# LPC43xx register map
File version: 5
Registers are 32-bit, read-write, reset 0x0 unless marked. A register's access mark holds for its fields unless they carry their own. Offsets are from the block's base; [hi:lo] are bit positions; {n}, {i} and the like mark numbered series.

## SPI — Product name title=UM10503 Chapter title=LPC43xx SPI Modification date=10/7/2011 Major revision=0 Minor revision=3
Base 0x40100000
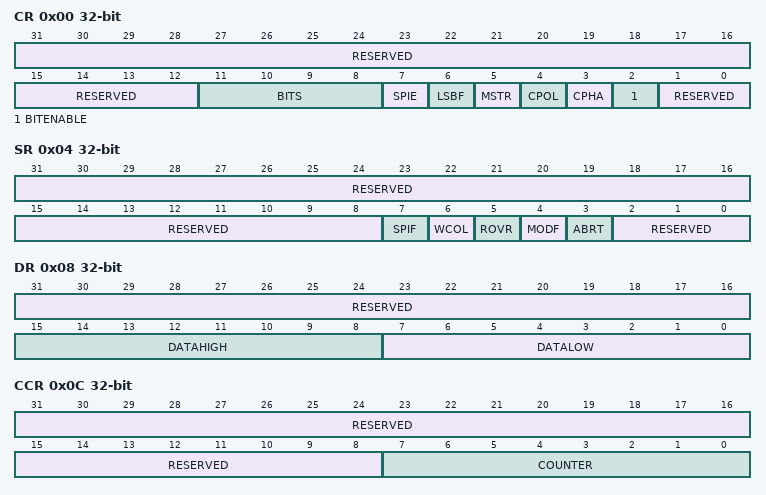
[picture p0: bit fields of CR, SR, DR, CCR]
0x00 CR — SPI Control Register. This register controls the operation of the SPI.
  [31:12] RESERVED — Reserved, user software should not write ones to reserved bits. The value read from a reserved bit is not defined.
  [11:8] BITS — When bit 2 of this register is 1, this field controls the number of bits per transfer:
    {v}={v}_BITS_PER_TRANSFER (v=8..15); 0=16_BITS_PER_TRANSFER
  [7] SPIE — Serial peripheral interrupt enable.
    0=INTBLOCK (SPI interrupts are inhibited.); 1=HWINT (A hardware interrupt is generated each time the SPIF or MODF bits are activated.)
  [6] LSBF — LSB First controls which direction each byte is shifted when transferred.
    0=MSB (SPI data is transferred MSB (bit 7) first.); 1=LSB (SPI data is transferred LSB (bit 0) first.)
  [5] MSTR — Master mode select.
    0=SLAVE (The SPI operates in Slave mode.); 1=MASTER (The SPI operates in Master mode.)
  [4] CPOL — Clock polarity control.
    0=SCK_IS_ACTIVE_HIGH_; 1=SCK_IS_ACTIVE_LOW_
  [3] CPHA — Clock phase control determines the relationship between the data and the clock on SPI transfers, and controls when a slave transfer is defined as starting and ending.
    0=FIRST_EDGE (Data is sampled on the first clock edge of SCK. A transfer starts and ends with activation and deactivation of the SSEL signal.); 1=SECOND_EDGE (Data is sampled on the second clock edge of the SCK. A transfer starts with the first clock edge, and ends with the last sampling edge when the SSEL signal is active.)
  [2] BITENABLE — The SPI controller sends and receives 8 bits of data per transfer.
    1=THE_SPI_CONTROLLER_S (The SPI controller sends and receives the number of bits selected by bits 11:8.)
  [1:0] RESERVED — Reserved, user software should not write ones to reserved bits. The value read from a reserved bit is not defined.
0x04 SR ro — SPI Status Register. This register shows the status of the SPI.
  [31:8] RESERVED — Reserved, user software should not write ones to reserved bits. The value read from a reserved bit is not defined.
  [7] SPIF — SPI transfer complete flag. When 1, this bit indicates when a SPI data transfer is complete. When a master, this bit is set at the end of the last cycle of the transfer. When a slave, this bit is set on the last data sampling edge of the SCK. This bit is cleared by first reading this register, then accessing the SPI Data Register. Note: this is not the SPI interrupt flag. This flag is found in the SPINT register.
  [6] WCOL — Write collision. When 1, this bit indicates that a write collision has occurred. This bit is cleared by reading this register, then accessing the SPI Data Register.
  [5] ROVR — Read overrun. When 1, this bit indicates that a read overrun has occurred. This bit is cleared by reading this register.
  [4] MODF — Mode fault. when 1, this bit indicates that a Mode fault error has occurred. This bit is cleared by reading this register, then writing the SPI0 control register.
  [3] ABRT — Slave abort. When 1, this bit indicates that a slave abort has occurred. This bit is cleared by reading this register.
  [2:0] RESERVED — Reserved, user software should not write ones to reserved bits. The value read from a reserved bit is not defined.
0x08 DR — SPI Data Register. This bi-directional register provides the transmit and receive data for the SPI. Transmit data is provided to the SPI0 by writing to this register. Data received by the SPI0 can be read from this register.
  [31:16] RESERVED — Reserved, user software should not write ones to reserved bits. The value read from a reserved bit is not defined.
  [15:8] DATAHIGH — If bit 2 of the SPCR is 1 and bits 11:8 are other than 1000, some or all of these bits contain the additional transmit and receive bits. When less than 16 bits are selected, the more significant among these bits read as zeroes.
  [7:0] DATALOW — SPI Bi-directional data port.
0x0C CCR — SPI Clock Counter Register. This register controls the frequency of a master's SCK0.
  [31:8] RESERVED — Reserved, user software should not write ones to reserved bits. The value read from a reserved bit is not defined.
  [7:0] COUNTER — SPI0 Clock counter setting.
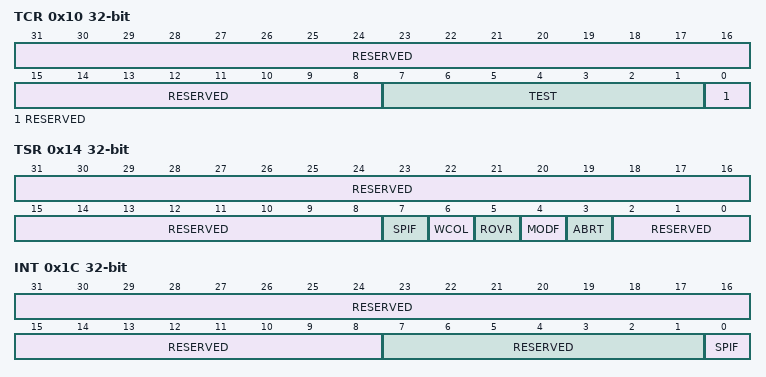
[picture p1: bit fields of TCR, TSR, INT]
0x10 TCR — SPI Test Control register. For functional testing only.
  [31:8] RESERVED — Reserved, user software should not write ones to reserved bits. The value read from a reserved bit is not defined.
  [7:1] TEST — SPI test mode. When 0, the SPI operates normally. When 1, SCK will always be on, independent of master mode select and data availability setting.
  [0] RESERVED — Reserved, user software should not write ones to reserved bits. The value read from a reserved bit is not defined.
0x14 TSR — SPI Test Status register. For functional testing only.
  [31:8] RESERVED — Reserved, user software should not write ones to reserved bits. The value read from a reserved bit is not defined.
  [7] SPIF — SPI transfer complete flag.
  [6] WCOL — Write collision.
  [5] ROVR — Read overrun.
  [4] MODF — Mode fault.
  [3] ABRT — Slave abort.
  [2:0] RESERVED — Reserved, user software should not write ones to reserved bits. The value read from a reserved bit is not defined.
0x1C INT — SPI Interrupt Flag. This register contains the interrupt flag for the SPI interface.
  [31:8] RESERVED — Reserved, user software should not write ones to reserved bits. The value read from a reserved bit is not defined.
  [7:1] RESERVED — Reserved, user software should not write ones to reserved bits. The value read from a reserved bit is not defined.
  [0] SPIF — SPI interrupt flag. Set by the SPI interface to generate an interrupt. Cleared by writing a 1 to this bit. Note: this bit will be set once when SPIE = 1 and at least one of SPIF and WCOL bits is 1. However, only when the SPI Interrupt bit is set and SPI0 Interrupt is enabled in the NVIC, SPI based interrupt can be processed by interrupt handling software.
